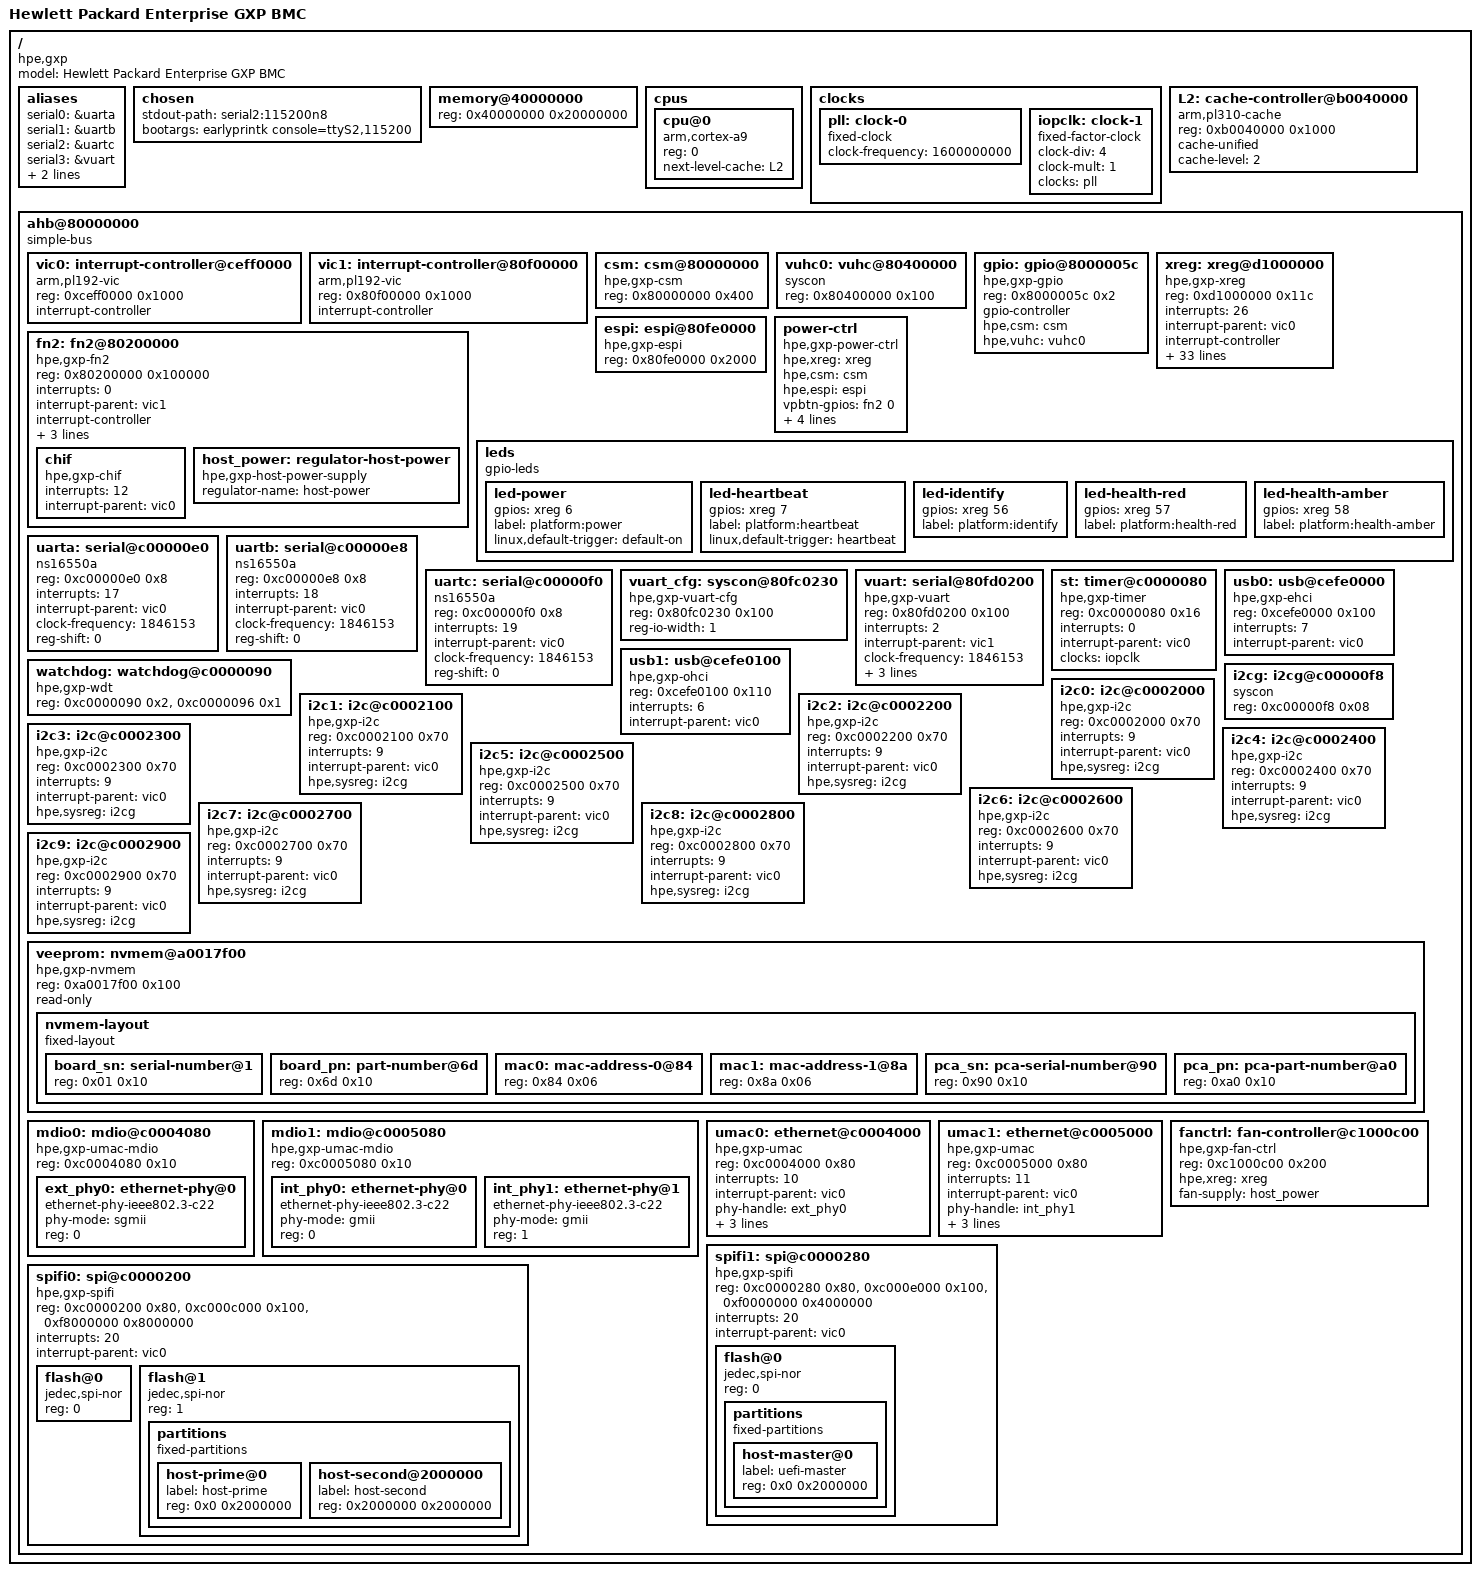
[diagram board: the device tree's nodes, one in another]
// SPDX-License-Identifier: GPL-2.0
/*
 * Device Tree file for HPE GXP
 */

/dts-v1/;
/ {
	model = "Hewlett Packard Enterprise GXP BMC";
	compatible = "hpe,gxp";
	#address-cells = <1>;
	#size-cells = <1>;

	aliases {
		serial0 = &uarta;
		serial1 = &uartb;
		serial2 = &uartc;
		serial3 = &vuart;
		ethernet0 = &umac0;
		ethernet1 = &umac1;
	};

	chosen {
		stdout-path = "serial2:115200n8";
		bootargs = "earlyprintk console=ttyS2,115200";
	};

	memory@40000000 {
		device_type = "memory";
		reg = <0x40000000 0x20000000>;
	};

	cpus {
		#address-cells = <1>;
		#size-cells = <0>;

		cpu@0 {
			compatible = "arm,cortex-a9";
			reg = <0>;
			device_type = "cpu";
			next-level-cache = <&L2>;
		};
	};

	clocks {
		pll: clock-0 {
			compatible = "fixed-clock";
			#clock-cells = <0>;
			clock-frequency = <1600000000>;
		};

		iopclk: clock-1 {
			compatible = "fixed-factor-clock";
			#clock-cells = <0>;
			clock-div = <4>;
			clock-mult = <1>;
			clocks = <&pll>;
		};
	};

	L2: cache-controller@b0040000 {
		compatible = "arm,pl310-cache";
		reg = <0xb0040000 0x1000>;
		cache-unified;
		cache-level = <2>;
	};

	ahb@80000000 {
		compatible = "simple-bus";
		#address-cells = <1>;
		#size-cells = <1>;
		ranges;

		vic0: interrupt-controller@ceff0000 {
			compatible = "arm,pl192-vic";
			reg = <0xceff0000 0x1000>;
			interrupt-controller;
			#interrupt-cells = <1>;
		};

		vic1: interrupt-controller@80f00000 {
			compatible = "arm,pl192-vic";
			reg = <0x80f00000 0x1000>;
			interrupt-controller;
			#interrupt-cells = <1>;
		};

		csm: csm@80000000 {
			compatible = "hpe,gxp-csm", "simple-mfd", "syscon";
			reg = <0x80000000 0x400>;
		};

		vuhc0: vuhc@80400000 {
			compatible = "syscon";
			reg = <0x80400000 0x100>;
		};

		gpio: gpio@8000005c {
			compatible = "hpe,gxp-gpio";
			reg = <0x8000005c 0x2>;
			gpio-controller;
			#gpio-cells = <2>;
			hpe,csm = <&csm>;
			hpe,vuhc = <&vuhc0>;
		};

		xreg: xreg@d1000000 {
			compatible = "hpe,gxp-xreg", "simple-mfd", "syscon";
			reg = <0xd1000000 0x11c>;
			interrupts = <26>;
			interrupt-parent = <&vic0>;
			interrupt-controller;
			#interrupt-cells = <2>;
			gpio-controller;
			#gpio-cells = <2>;

			gpio-line-names =
				/* 0-7: IOP LEDs */
				"iop-led1", "iop-led2", "iop-led3", "iop-led4",
				"iop-led5", "iop-led6", "iop-led7", "iop-led8",
				/* 8-23: Fan installed status */
				"fan1-installed", "fan2-installed",
				"fan3-installed", "fan4-installed",
				"fan5-installed", "fan6-installed",
				"fan7-installed", "fan8-installed",
				"fan9-installed", "fan10-installed",
				"fan11-installed", "fan12-installed",
				"fan13-installed", "fan14-installed",
				"fan15-installed", "fan16-installed",
				/* 24-39: Fan fail status (active low) */
				"fan1-fail", "fan2-fail",
				"fan3-fail", "fan4-fail",
				"fan5-fail", "fan6-fail",
				"fan7-fail", "fan8-fail",
				"fan9-fail", "fan10-fail",
				"fan11-fail", "fan12-fail",
				"fan13-fail", "fan14-fail",
				"fan15-fail", "fan16-fail",
				/* 40-55: Fan ID */
				"fan1-id", "fan2-id",
				"fan3-id", "fan4-id",
				"fan5-id", "fan6-id",
				"fan7-id", "fan8-id",
				"fan9-id", "fan10-id",
				"fan11-id", "fan12-id",
				"fan13-id", "fan14-id",
				"fan15-id", "fan16-id",
				/* 56-58: Status LEDs */
				"led-identify", "led-health-red", "led-health-amber",
				/* 59-61: Button interrupts */
				"power-button", "uid-button", "sleep-button",
				/* 62-69: Reserved */
				"", "", "", "", "", "", "", "",
				/* 70-72: ACM control */
				"acm-force-off", "acm-removed", "acm-req-n",
				/* 73-89: Reserved */
				"", "", "", "", "", "", "", "",
				"", "", "", "", "", "", "", "", "",
				/* 90-97: PSU installed */
				"psu1-installed", "psu2-installed",
				"psu3-installed", "psu4-installed",
				"psu5-installed", "psu6-installed",
				"psu7-installed", "psu8-installed",
				/* 98-99: Reserved */
				"", "",
				/* 100-107: PSU AC OK */
				"psu1-ac-ok", "psu2-ac-ok",
				"psu3-ac-ok", "psu4-ac-ok",
				"psu5-ac-ok", "psu6-ac-ok",
				"psu7-ac-ok", "psu8-ac-ok",
				/* 108-109: Reserved */
				"", "",
				/* 110-117: PSU DC OK */
				"psu1-dc-ok", "psu2-dc-ok",
				"psu3-dc-ok", "psu4-dc-ok",
				"psu5-dc-ok", "psu6-dc-ok",
				"psu7-dc-ok", "psu8-dc-ok";
		};

		fn2: fn2@80200000 {
			compatible = "hpe,gxp-fn2", "simple-mfd", "syscon";
			reg = <0x80200000 0x100000>;
			interrupts = <0>;
			interrupt-parent = <&vic1>;
			interrupt-controller;
			#interrupt-cells = <2>;
			gpio-controller;
			#gpio-cells = <2>;

			gpio-line-names =
				/* 0: Virtual power button (output) */
				"vpbtn",
				/* 1: Power good (input) */
				"pgood",
				/* 2: PCIe reset (input) */
				"perst",
				/* 3: POST complete (input) */
				"post-complete",
				/* 4: Button state (input) */
				"btn-state";

			chif: chif {
				compatible = "hpe,gxp-chif";
				interrupts = <12>;
				interrupt-parent = <&vic0>;
			};

			host_power: regulator-host-power {
				compatible = "hpe,gxp-host-power-supply";
				regulator-name = "host-power";
			};
		};

		espi: espi@80fe0000 {
			compatible = "hpe,gxp-espi", "syscon";
			reg = <0x80fe0000 0x2000>;
		};

		power-ctrl {
			compatible = "hpe,gxp-power-ctrl";
			hpe,xreg = <&xreg>;
			hpe,csm = <&csm>;
			hpe,espi = <&espi>;
			vpbtn-gpios = <&fn2 0 0>;
			pgood-gpios = <&fn2 1 0>;
			gpio-controller;
			#gpio-cells = <2>;
			gpio-line-names = "power-ctrl-out", "power-ctrl-good", "reset-out";
		};

		leds {
			compatible = "gpio-leds";

			led-power {
				gpios = <&xreg 6 0>;
				label = "platform:power";
				linux,default-trigger = "default-on";
			};

			led-heartbeat {
				gpios = <&xreg 7 0>;
				label = "platform:heartbeat";
				linux,default-trigger = "heartbeat";
			};

			led-identify {
				gpios = <&xreg 56 0>;
				label = "platform:identify";
			};

			led-health-red {
				gpios = <&xreg 57 0>;
				label = "platform:health-red";
			};

			led-health-amber {
				gpios = <&xreg 58 0>;
				label = "platform:health-amber";
			};
		};

		uarta: serial@c00000e0 {
			compatible = "ns16550a";
			reg = <0xc00000e0 0x8>;
			interrupts = <17>;
			interrupt-parent = <&vic0>;
			clock-frequency = <1846153>;
			reg-shift = <0>;
		};

		uartb: serial@c00000e8 {
			compatible = "ns16550a";
			reg = <0xc00000e8 0x8>;
			interrupts = <18>;
			interrupt-parent = <&vic0>;
			clock-frequency = <1846153>;
			reg-shift = <0>;
		};

		uartc: serial@c00000f0 {
			compatible = "ns16550a";
			reg = <0xc00000f0 0x8>;
			interrupts = <19>;
			interrupt-parent = <&vic0>;
			clock-frequency = <1846153>;
			reg-shift = <0>;
		};

		vuart_cfg: syscon@80fc0230 {
			compatible = "hpe,gxp-vuart-cfg", "syscon";
			reg = <0x80fc0230 0x100>;
			reg-io-width = <1>;
		};

		vuart: serial@80fd0200 {
			compatible = "hpe,gxp-vuart";
			reg = <0x80fd0200 0x100>;
			interrupts = <2>;
			interrupt-parent = <&vic1>;
			clock-frequency = <1846153>;
			reg-shift = <0>;
			serial-line = <3>;
			vuart-cfg = <&vuart_cfg>;
		};

		st: timer@c0000080 {
			compatible = "hpe,gxp-timer";
			reg = <0xc0000080 0x16>;
			interrupts = <0>;
			interrupt-parent = <&vic0>;
			clocks = <&iopclk>;
			clock-names = "iop";
		};

		watchdog: watchdog@c0000090 {
			compatible = "hpe,gxp-wdt";
			reg = <0xc0000090 0x2>, <0xc0000096 0x1>;
		};

		usb0: usb@cefe0000 {
			compatible = "hpe,gxp-ehci", "generic-ehci";
			reg = <0xcefe0000 0x100>;
			interrupts = <7>;
			interrupt-parent = <&vic0>;
		};

		usb1: usb@cefe0100 {
			compatible = "hpe,gxp-ohci", "generic-ohci";
			reg = <0xcefe0100 0x110>;
			interrupts = <6>;
			interrupt-parent = <&vic0>;
		};

		i2cg: i2cg@c00000f8 {
			compatible = "syscon";
			reg = <0xc00000f8 0x08>;
		};

		i2c0: i2c@c0002000 {
			compatible = "hpe,gxp-i2c";
			reg = <0xc0002000 0x70>;
			interrupts = <9>;
			interrupt-parent = <&vic0>;
			hpe,sysreg = <&i2cg>;
			#address-cells = <1>;
			#size-cells = <0>;
		};

		i2c1: i2c@c0002100 {
			compatible = "hpe,gxp-i2c";
			reg = <0xc0002100 0x70>;
			interrupts = <9>;
			interrupt-parent = <&vic0>;
			hpe,sysreg = <&i2cg>;
			#address-cells = <1>;
			#size-cells = <0>;
		};

		i2c2: i2c@c0002200 {
			compatible = "hpe,gxp-i2c";
			reg = <0xc0002200 0x70>;
			interrupts = <9>;
			interrupt-parent = <&vic0>;
			hpe,sysreg = <&i2cg>;
			#address-cells = <1>;
			#size-cells = <0>;
		};

		i2c3: i2c@c0002300 {
			compatible = "hpe,gxp-i2c";
			reg = <0xc0002300 0x70>;
			interrupts = <9>;
			interrupt-parent = <&vic0>;
			hpe,sysreg = <&i2cg>;
			#address-cells = <1>;
			#size-cells = <0>;
		};

		i2c4: i2c@c0002400 {
			compatible = "hpe,gxp-i2c";
			reg = <0xc0002400 0x70>;
			interrupts = <9>;
			interrupt-parent = <&vic0>;
			hpe,sysreg = <&i2cg>;
			#address-cells = <1>;
			#size-cells = <0>;
		};

		i2c5: i2c@c0002500 {
			compatible = "hpe,gxp-i2c";
			reg = <0xc0002500 0x70>;
			interrupts = <9>;
			interrupt-parent = <&vic0>;
			hpe,sysreg = <&i2cg>;
			#address-cells = <1>;
			#size-cells = <0>;
		};

		i2c6: i2c@c0002600 {
			compatible = "hpe,gxp-i2c";
			reg = <0xc0002600 0x70>;
			interrupts = <9>;
			interrupt-parent = <&vic0>;
			hpe,sysreg = <&i2cg>;
			#address-cells = <1>;
			#size-cells = <0>;
		};

		i2c7: i2c@c0002700 {
			compatible = "hpe,gxp-i2c";
			reg = <0xc0002700 0x70>;
			interrupts = <9>;
			interrupt-parent = <&vic0>;
			hpe,sysreg = <&i2cg>;
			#address-cells = <1>;
			#size-cells = <0>;
		};

		i2c8: i2c@c0002800 {
			compatible = "hpe,gxp-i2c";
			reg = <0xc0002800 0x70>;
			interrupts = <9>;
			interrupt-parent = <&vic0>;
			hpe,sysreg = <&i2cg>;
			#address-cells = <1>;
			#size-cells = <0>;
		};

		i2c9: i2c@c0002900 {
			compatible = "hpe,gxp-i2c";
			reg = <0xc0002900 0x70>;
			interrupts = <9>;
			interrupt-parent = <&vic0>;
			hpe,sysreg = <&i2cg>;
			#address-cells = <1>;
			#size-cells = <0>;
		};

		veeprom: nvmem@a0017f00 {
			compatible = "hpe,gxp-nvmem";
			reg = <0xa0017f00 0x100>;
			read-only;

			nvmem-layout {
				compatible = "fixed-layout";
				#address-cells = <1>;
				#size-cells = <1>;

				board_sn: serial-number@1 {
					reg = <0x01 0x10>;
				};

				board_pn: part-number@6d {
					reg = <0x6d 0x10>;
				};

				mac0: mac-address-0@84 {
					reg = <0x84 0x06>;
				};

				mac1: mac-address-1@8a {
					reg = <0x8a 0x06>;
				};

				pca_sn: pca-serial-number@90 {
					reg = <0x90 0x10>;
				};

				pca_pn: pca-part-number@a0 {
					reg = <0xa0 0x10>;
				};
			};
		};

		mdio0: mdio@c0004080 {
			compatible = "hpe,gxp-umac-mdio";
			reg = <0xc0004080 0x10>;
			#address-cells = <1>;
			#size-cells = <0>;

			ext_phy0: ethernet-phy@0 {
				compatible = "ethernet-phy-ieee802.3-c22";
				phy-mode = "sgmii";
				reg = <0>;
			};
		};

		mdio1: mdio@c0005080 {
			compatible = "hpe,gxp-umac-mdio";
			reg = <0xc0005080 0x10>;
			#address-cells = <1>;
			#size-cells = <0>;

			int_phy0: ethernet-phy@0 {
				compatible = "ethernet-phy-ieee802.3-c22";
				phy-mode = "gmii";
				reg = <0>;
			};

			int_phy1: ethernet-phy@1 {
				compatible = "ethernet-phy-ieee802.3-c22";
				phy-mode = "gmii";
				reg = <1>;
			};
		};

		umac0: ethernet@c0004000 {
			compatible = "hpe,gxp-umac";
			reg = <0xc0004000 0x80>;
			interrupts = <10>;
			interrupt-parent = <&vic0>;
			phy-handle = <&ext_phy0>;
			int-phy-handle = <&int_phy0>;
			nvmem-cells = <&mac0>;
			nvmem-cell-names = "mac-address";
		};

		umac1: ethernet@c0005000 {
			compatible = "hpe,gxp-umac";
			reg = <0xc0005000 0x80>;
			interrupts = <11>;
			interrupt-parent = <&vic0>;
			phy-handle = <&int_phy1>;
			use-ncsi;
			nvmem-cells = <&mac1>;
			nvmem-cell-names = "mac-address";
		};

		fanctrl: fan-controller@c1000c00 {
			compatible = "hpe,gxp-fan-ctrl";
			reg = <0xc1000c00 0x200>;
			hpe,xreg = <&xreg>;
			fan-supply = <&host_power>;
		};

		spifi1: spi@c0000280 {
			compatible = "hpe,gxp-spifi";
			reg = <0xc0000280 0x80>, <0xc000e000 0x100>, <0xf0000000 0x4000000>;
			interrupts = <20>;
			interrupt-parent = <&vic0>;
			#address-cells = <1>;
			#size-cells = <0>;

			flash@0 {
				compatible = "jedec,spi-nor";
				reg = <0>;
				partitions {
					compatible = "fixed-partitions";
					#address-cells = <1>;
					#size-cells = <1>;

					host-master@0 {
						label = "uefi-master";
						reg = <0x0 0x2000000>;
					};
				};
			};
		};

		spifi0: spi@c0000200 {
			compatible = "hpe,gxp-spifi";
			reg = <0xc0000200 0x80>, <0xc000c000 0x100>, <0xf8000000 0x8000000>;
			interrupts = <20>;
			interrupt-parent = <&vic0>;
			#address-cells = <1>;
			#size-cells = <0>;

			flash@0 {
				compatible = "jedec,spi-nor";
				reg = <0>;
				#include "gxp-bmc-flash-layout.dtsi"
			};

			flash@1 {
				compatible = "jedec,spi-nor";
				reg = <1>;
				partitions {
					compatible = "fixed-partitions";
					#address-cells = <1>;
					#size-cells = <1>;

					host-prime@0 {
						label = "host-prime";
						reg = <0x0 0x2000000>;
					};
					host-second@2000000 {
						label = "host-second";
						reg = <0x2000000 0x2000000>;
					};
				};
			};
		};
	};
};
